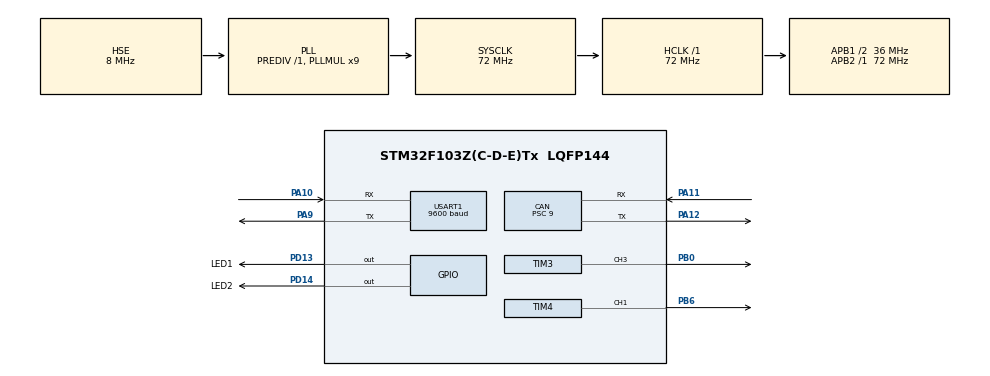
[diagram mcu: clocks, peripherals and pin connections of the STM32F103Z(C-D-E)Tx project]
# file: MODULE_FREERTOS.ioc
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CAN.ABOM=ENABLE
CAN.BS1=CAN_BS1_5TQ
CAN.BS2=CAN_BS2_2TQ
CAN.CalculateTimeBit=2000
CAN.CalculateTimeQuantum=250.0
CAN.Prescaler=9
CAN.SJW=CAN_SJW_3TQ
Dma.Request0=TIM3_CH3
Dma.Request1=TIM4_CH1
Dma.TIM3_CH3.0.Direction=DMA_MEMORY_TO_PERIPH
Dma.TIM3_CH3.0.Instance=DMA1_Channel2
Dma.TIM3_CH3.0.MemDataAlignment=DMA_MDATAALIGN_HALFWORD
Dma.TIM3_CH3.0.MemInc=DMA_MINC_ENABLE
Dma.TIM3_CH3.0.Mode=DMA_NORMAL
Dma.TIM3_CH3.0.PeriphDataAlignment=DMA_PDATAALIGN_HALFWORD
Dma.TIM3_CH3.0.PeriphInc=DMA_PINC_DISABLE
Dma.TIM3_CH3.0.Priority=DMA_PRIORITY_HIGH
Dma.TIM4_CH1.1.Direction=DMA_MEMORY_TO_PERIPH
Dma.TIM4_CH1.1.Instance=DMA1_Channel1
Dma.TIM4_CH1.1.MemDataAlignment=DMA_MDATAALIGN_HALFWORD
Dma.TIM4_CH1.1.MemInc=DMA_MINC_ENABLE
Dma.TIM4_CH1.1.Mode=DMA_NORMAL
Dma.TIM4_CH1.1.PeriphDataAlignment=DMA_PDATAALIGN_HALFWORD
Dma.TIM4_CH1.1.PeriphInc=DMA_PINC_DISABLE
Dma.TIM4_CH1.1.Priority=DMA_PRIORITY_HIGH
FREERTOS.INCLUDE_pcTaskGetTaskName=1
FREERTOS.INCLUDE_uxTaskGetStackHighWaterMark=1
FREERTOS.INCLUDE_xSemaphoreGetMutexHolder=1
FREERTOS.Tasks01=defaultTask,0,128,StartDefaultTask,Default,NULL
FREERTOS.configMINIMAL_STACK_SIZE=64
FREERTOS.configTOTAL_HEAP_SIZE=5120
FREERTOS.configUSE_COUNTING_SEMAPHORES=1
Mcu.Family=STM32F1
Mcu.Name=STM32F103Z(C-D-E)Tx
Mcu.Package=LQFP144
NVIC.DMA1_Channel1_IRQn=true\:5\:0\:false\:false\:true\:true\:false
NVIC.DMA1_Channel2_IRQn=true\:5\:0\:false\:false\:true\:true\:false
NVIC.PriorityGroup=NVIC_PRIORITYGROUP_4
NVIC.TIM7_IRQn=true\:0\:0\:false\:false\:true\:false\:false
NVIC.TimeBase=TIM7_IRQn
NVIC.TimeBaseIP=TIM7
NVIC.USB_LP_CAN1_RX0_IRQn=true\:5\:0\:false\:false\:true\:true\:true
OSC_IN.Mode=HSE-External-Oscillator
OSC_IN.Signal=RCC_OSC_IN
OSC_OUT.Mode=HSE-External-Oscillator
OSC_OUT.Signal=RCC_OSC_OUT
PA10.Mode=Asynchronous
PA10.Signal=USART1_RX
PA11.Mode=Master
PA11.Signal=CAN_RX
PA12.Mode=Master
PA12.Signal=CAN_TX
PA13.Mode=Serial_Wire
PA13.Signal=SYS_JTMS-SWDIO
PA14.Mode=Serial_Wire
PA14.Signal=SYS_JTCK-SWCLK
PA9.Mode=Asynchronous
PA9.Signal=USART1_TX
PB0.Signal=S_TIM3_CH3
PB6.Signal=S_TIM4_CH1
PD13.GPIO_Label=LED1
PD13.GPIO_Speed=GPIO_SPEED_FREQ_HIGH
PD13.Signal=GPIO_Output
PD14.GPIO_Label=LED2
PD14.GPIO_Speed=GPIO_SPEED_FREQ_HIGH
PD14.Signal=GPIO_Output
ProjectManager.HeapSize=0x200
ProjectManager.StackSize=0x400
ProjectManager.TargetToolchain=MDK-ARM V5
RCC.AHBFreq_Value=72000000
RCC.APB1CLKDivider=RCC_HCLK_DIV2
RCC.APB1Freq_Value=36000000
RCC.APB1TimFreq_Value=72000000
RCC.APB2Freq_Value=72000000
RCC.APB2TimFreq_Value=72000000
RCC.HCLKFreq_Value=72000000
RCC.PLLMUL=RCC_PLL_MUL9
RCC.PLLSourceVirtual=RCC_PLLSOURCE_HSE
RCC.SYSCLKFreq_VALUE=72000000
RCC.SYSCLKSource=RCC_SYSCLKSOURCE_PLLCLK
RCC.USBFreq_Value=72000000
SH.S_TIM3_CH3.0=TIM3_CH3,PWM Generation3 CH3
SH.S_TIM4_CH1.0=TIM4_CH1,PWM Generation1 CH1
TIM3.Channel-PWM\ Generation3\ CH3=TIM_CHANNEL_3
TIM4.Channel-PWM\ Generation1\ CH1=TIM_CHANNEL_1
USART1.BaudRate=9600
USART1.VirtualMode=VM_ASYNC
VP_FREERTOS_VS_ENABLE.Mode=Enabled
VP_SYS_VS_tim7.Mode=TIM7
board=MODULE_FREERTOS

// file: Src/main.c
/**
  ******************************************************************************
  * @file           : main.c
  * @brief          : Main program body
  ******************************************************************************
  * This notice applies to any and all portions of this file
  * that are not between comment pairs USER CODE BEGIN and
  * USER CODE END. Other portions of this file, whether
  * inserted by the user or by software development tools
  * are owned by their respective copyright owners.
  *
  * Copyright (c) 2018 STMicroelectronics International N.V.
  * All rights reserved.
  *
  * Redistribution and use in source and binary forms, with or without
  * modification, are permitted, provided that the following conditions are met:
  *
  * 1. Redistribution of source code must retain the above copyright notice,
  *    this list of conditions and the following disclaimer.
  * 2. Redistributions in binary form must reproduce the above copyright notice,
  *    this list of conditions and the following disclaimer in the documentation
  *    and/or other materials provided with the distribution.
  * 3. Neither the name of STMicroelectronics nor the names of other
  *    contributors to this software may be used to endorse or promote products
  *    derived from this software without specific written permission.
  * 4. This software, including modifications and/or derivative works of this
  *    software, must execute solely and exclusively on microcontroller or
  *    microprocessor devices manufactured by or for STMicroelectronics.
  * 5. Redistribution and use of this software other than as permitted under
  *    this license is void and will automatically terminate your rights under
  *    this license.
  *
  * THIS SOFTWARE IS PROVIDED BY STMICROELECTRONICS AND CONTRIBUTORS "AS IS"
  * AND ANY EXPRESS, IMPLIED OR STATUTORY WARRANTIES, INCLUDING, BUT NOT
  * LIMITED TO, THE IMPLIED WARRANTIES OF MERCHANTABILITY, FITNESS FOR A
  * PARTICULAR PURPOSE AND NON-INFRINGEMENT OF THIRD PARTY INTELLECTUAL PROPERTY
  * RIGHTS ARE DISCLAIMED TO THE FULLEST EXTENT PERMITTED BY LAW. IN NO EVENT
  * SHALL STMICROELECTRONICS OR CONTRIBUTORS BE LIABLE FOR ANY DIRECT, INDIRECT,
  * INCIDENTAL, SPECIAL, EXEMPLARY, OR CONSEQUENTIAL DAMAGES (INCLUDING, BUT NOT
  * LIMITED TO, PROCUREMENT OF SUBSTITUTE GOODS OR SERVICES; LOSS OF USE, DATA,
  * OR PROFITS; OR BUSINESS INTERRUPTION) HOWEVER CAUSED AND ON ANY THEORY OF
  * LIABILITY, WHETHER IN CONTRACT, STRICT LIABILITY, OR TORT (INCLUDING
  * NEGLIGENCE OR OTHERWISE) ARISING IN ANY WAY OUT OF THE USE OF THIS SOFTWARE,
  * EVEN IF ADVISED OF THE POSSIBILITY OF SUCH DAMAGE.
  *
  ******************************************************************************
  */
#include "main.h"
#include "stm32f1xx_hal.h"
#include "cmsis_os.h"

/* USER CODE BEGIN Includes */
#include "usart.h"
#include "can.h"
#include "color.h"
#include "ledstrip.h"
/* USER CODE END Includes */

CAN_HandleTypeDef hcan;

TIM_HandleTypeDef htim3;
TIM_HandleTypeDef htim4;
DMA_HandleTypeDef hdma_tim3_ch3;
DMA_HandleTypeDef hdma_tim4_ch1;

UART_HandleTypeDef huart1;

osThreadId defaultTaskHandle;

/* USER CODE BEGIN PV */
/* Private variables ---------------------------------------------------------*/

/* USER CODE END PV */

void SystemClock_Config(void);
static void MX_GPIO_Init(void);
static void MX_DMA_Init(void);
static void MX_CAN_Init(void);
static void MX_USART1_UART_Init(void);
static void MX_TIM3_Init(void);
static void MX_TIM4_Init(void);
void StartDefaultTask(void const * argument);

void HAL_TIM_MspPostInit(TIM_HandleTypeDef *htim);

/* USER CODE BEGIN PFP */
/* Private function prototypes -----------------------------------------------*/

/* USER CODE END PFP */

int main(void)
{

  /* MCU Configuration----------------------------------------------------------*/

  /* Reset of all peripherals, Initializes the Flash interface and the Systick. */
  HAL_Init();

  /* Configure the system clock */
  SystemClock_Config();

  /* Initialize all configured peripherals */
  MX_GPIO_Init();
  MX_DMA_Init();
  MX_CAN_Init();
  MX_USART1_UART_Init();
  MX_TIM3_Init();
  MX_TIM4_Init();

  /* Create the thread(s) */
  /* definition and creation of defaultTask */
  osThreadDef(defaultTask, StartDefaultTask, osPriorityNormal, 0, 128);
  defaultTaskHandle = osThreadCreate(osThread(defaultTask), NULL);

  /* Start scheduler */
  osKernelStart();

  /* We should never get here as control is now taken by the scheduler */

  /* Infinite loop */
  while (1)
  {

  }

}

void SystemClock_Config(void)
{

  RCC_OscInitTypeDef RCC_OscInitStruct;
  RCC_ClkInitTypeDef RCC_ClkInitStruct;

    /**Initializes the CPU, AHB and APB busses clocks
    */
  RCC_OscInitStruct.OscillatorType = RCC_OSCILLATORTYPE_HSE;
  RCC_OscInitStruct.HSEState = RCC_HSE_ON;
  RCC_OscInitStruct.HSEPredivValue = RCC_HSE_PREDIV_DIV1;
  RCC_OscInitStruct.HSIState = RCC_HSI_ON;
  RCC_OscInitStruct.PLL.PLLState = RCC_PLL_ON;
  RCC_OscInitStruct.PLL.PLLSource = RCC_PLLSOURCE_HSE;
  RCC_OscInitStruct.PLL.PLLMUL = RCC_PLL_MUL9;
  if (HAL_RCC_OscConfig(&RCC_OscInitStruct) != HAL_OK)
  {
    _Error_Handler(__FILE__, __LINE__);
  }

    /**Initializes the CPU, AHB and APB busses clocks
    */
  RCC_ClkInitStruct.ClockType = RCC_CLOCKTYPE_HCLK|RCC_CLOCKTYPE_SYSCLK
                              |RCC_CLOCKTYPE_PCLK1|RCC_CLOCKTYPE_PCLK2;
  RCC_ClkInitStruct.SYSCLKSource = RCC_SYSCLKSOURCE_PLLCLK;
  RCC_ClkInitStruct.AHBCLKDivider = RCC_SYSCLK_DIV1;
  RCC_ClkInitStruct.APB1CLKDivider = RCC_HCLK_DIV2;
  RCC_ClkInitStruct.APB2CLKDivider = RCC_HCLK_DIV1;

  if (HAL_RCC_ClockConfig(&RCC_ClkInitStruct, FLASH_LATENCY_2) != HAL_OK)
  {
    _Error_Handler(__FILE__, __LINE__);
  }

    /**Configure the Systick interrupt time
    */
  HAL_SYSTICK_Config(HAL_RCC_GetHCLKFreq()/1000);

    /**Configure the Systick
    */
  HAL_SYSTICK_CLKSourceConfig(SYSTICK_CLKSOURCE_HCLK);

  /* SysTick_IRQn interrupt configuration */
  HAL_NVIC_SetPriority(SysTick_IRQn, 15, 0);
}

/* CAN init function */
static void MX_CAN_Init(void)
{

  hcan.Instance = CAN1;
  hcan.Init.Prescaler = 9;
  hcan.Init.Mode = CAN_MODE_NORMAL;
  hcan.Init.SJW = CAN_SJW_3TQ;
  hcan.Init.BS1 = CAN_BS1_5TQ;
  hcan.Init.BS2 = CAN_BS2_2TQ;
  hcan.Init.TTCM = DISABLE;
  hcan.Init.ABOM = ENABLE;
  hcan.Init.AWUM = DISABLE;
  hcan.Init.NART = DISABLE;
  hcan.Init.RFLM = DISABLE;
  hcan.Init.TXFP = DISABLE;
  if (HAL_CAN_Init(&hcan) != HAL_OK)
  {
    _Error_Handler(__FILE__, __LINE__);
  }

}

/* TIM3 init function */
static void MX_TIM3_Init(void)
{

  TIM_MasterConfigTypeDef sMasterConfig;
  TIM_OC_InitTypeDef sConfigOC;

  htim3.Instance = TIM3;
  htim3.Init.Prescaler = 0;
  htim3.Init.CounterMode = TIM_COUNTERMODE_UP;
  htim3.Init.Period = 0;
  htim3.Init.ClockDivision = TIM_CLOCKDIVISION_DIV1;
  htim3.Init.AutoReloadPreload = TIM_AUTORELOAD_PRELOAD_DISABLE;
  if (HAL_TIM_PWM_Init(&htim3) != HAL_OK)
  {
    _Error_Handler(__FILE__, __LINE__);
  }

  sMasterConfig.MasterOutputTrigger = TIM_TRGO_RESET;
  sMasterConfig.MasterSlaveMode = TIM_MASTERSLAVEMODE_DISABLE;
  if (HAL_TIMEx_MasterConfigSynchronization(&htim3, &sMasterConfig) != HAL_OK)
  {
    _Error_Handler(__FILE__, __LINE__);
  }

  sConfigOC.OCMode = TIM_OCMODE_PWM1;
  sConfigOC.Pulse = 0;
  sConfigOC.OCPolarity = TIM_OCPOLARITY_HIGH;
  sConfigOC.OCFastMode = TIM_OCFAST_DISABLE;
  if (HAL_TIM_PWM_ConfigChannel(&htim3, &sConfigOC, TIM_CHANNEL_3) != HAL_OK)
  {
    _Error_Handler(__FILE__, __LINE__);
  }

  HAL_TIM_MspPostInit(&htim3);

}

/* TIM4 init function */
static void MX_TIM4_Init(void)
{

  TIM_MasterConfigTypeDef sMasterConfig;
  TIM_OC_InitTypeDef sConfigOC;

  htim4.Instance = TIM4;
  htim4.Init.Prescaler = 0;
  htim4.Init.CounterMode = TIM_COUNTERMODE_UP;
  htim4.Init.Period = 0;
  htim4.Init.ClockDivision = TIM_CLOCKDIVISION_DIV1;
  htim4.Init.AutoReloadPreload = TIM_AUTORELOAD_PRELOAD_DISABLE;
  if (HAL_TIM_PWM_Init(&htim4) != HAL_OK)
  {
    _Error_Handler(__FILE__, __LINE__);
  }

  sMasterConfig.MasterOutputTrigger = TIM_TRGO_RESET;
  sMasterConfig.MasterSlaveMode = TIM_MASTERSLAVEMODE_DISABLE;
  if (HAL_TIMEx_MasterConfigSynchronization(&htim4, &sMasterConfig) != HAL_OK)
  {
    _Error_Handler(__FILE__, __LINE__);
  }

  sConfigOC.OCMode = TIM_OCMODE_PWM1;
  sConfigOC.Pulse = 0;
  sConfigOC.OCPolarity = TIM_OCPOLARITY_HIGH;
  sConfigOC.OCFastMode = TIM_OCFAST_DISABLE;
  if (HAL_TIM_PWM_ConfigChannel(&htim4, &sConfigOC, TIM_CHANNEL_1) != HAL_OK)
  {
    _Error_Handler(__FILE__, __LINE__);
  }

  HAL_TIM_MspPostInit(&htim4);

}

/* USART1 init function */
static void MX_USART1_UART_Init(void)
{

  huart1.Instance = USART1;
  huart1.Init.BaudRate = 9600;
  huart1.Init.WordLength = UART_WORDLENGTH_8B;
  huart1.Init.StopBits = UART_STOPBITS_1;
  huart1.Init.Parity = UART_PARITY_NONE;
  huart1.Init.Mode = UART_MODE_TX_RX;
  huart1.Init.HwFlowCtl = UART_HWCONTROL_NONE;
  huart1.Init.OverSampling = UART_OVERSAMPLING_16;
  if (HAL_UART_Init(&huart1) != HAL_OK)
  {
    _Error_Handler(__FILE__, __LINE__);
  }

}

static void MX_DMA_Init(void)
{
  /* DMA controller clock enable */
  __HAL_RCC_DMA1_CLK_ENABLE();

  /* DMA interrupt init */
  /* DMA1_Channel1_IRQn interrupt configuration */
  HAL_NVIC_SetPriority(DMA1_Channel1_IRQn, 5, 0);
  HAL_NVIC_EnableIRQ(DMA1_Channel1_IRQn);
  /* DMA1_Channel2_IRQn interrupt configuration */
  HAL_NVIC_SetPriority(DMA1_Channel2_IRQn, 5, 0);
  HAL_NVIC_EnableIRQ(DMA1_Channel2_IRQn);

}

/** Configure pins as
        * Analog
        * Input
        * Output
        * EVENT_OUT
        * EXTI
*/
static void MX_GPIO_Init(void)
{

  GPIO_InitTypeDef GPIO_InitStruct;

  /* GPIO Ports Clock Enable */
  __HAL_RCC_GPIOB_CLK_ENABLE();
  __HAL_RCC_GPIOD_CLK_ENABLE();
  __HAL_RCC_GPIOA_CLK_ENABLE();

  /*Configure GPIO pin Output Level */
  HAL_GPIO_WritePin(GPIOD, LED1_Pin|LED2_Pin, GPIO_PIN_RESET);

  /*Configure GPIO pins : LED1_Pin LED2_Pin */
  GPIO_InitStruct.Pin = LED1_Pin|LED2_Pin;
  GPIO_InitStruct.Mode = GPIO_MODE_OUTPUT_PP;
  GPIO_InitStruct.Speed = GPIO_SPEED_FREQ_HIGH;
  HAL_GPIO_Init(GPIOD, &GPIO_InitStruct);

}

/* StartDefaultTask function */
void StartDefaultTask(void const * argument)
{

  for(;;)
  {
    osDelay(1);
  }
}

void HAL_TIM_PeriodElapsedCallback(TIM_HandleTypeDef *htim)
{
  if (htim->Instance == TIM7) {
    HAL_IncTick();
  }
}

void _Error_Handler(char *file, int line)
{
  while(1)
  {
  }
}

/************************ (C) COPYRIGHT STMicroelectronics *****END OF FILE****/
